# RK3399-AP register map
File version: 1
CPU: CA7 r0p1, little endian, MPU, FPU, I-cache, D-cache, VTOR, 4 interrupt priority bits, 32 interrupts
Registers are 32-bit, read-write, reset 0x0 unless marked. A register's access mark holds for its fields unless they carry their own. Offsets are from the block's base; [hi:lo] are bit positions.

## GPIO0
Base 0xFF720000
Same registers: GPIO1 0xFF730000, GPIO2 0xFF780000, GPIO3 0xFF788000, GPIO4 0xFF790000
0x00 GPIO_SWPORTA_DR — Port A data register
  [31:0] GPIO_SWPORTA_DR — Values written to this register are output on the I/O signals for Port A if the corresponding data direction bits for Port A are set to Output mode. The value read back is equal to the last value written to this register.
0x04 GPIO_SWPORTA_DDR — Port A data direction register
  [31:0] GPIO_SWPORTA_DDR — Values written to this register independently control the direction of the corresponding data bit in Port A. 0: Input (default) 1: Output
0x30 GPIO_INTEN — Interrupt enable register
  [31:0] GPIO_INT_EN — Allows each bit of Port A to be configured for interrupts. Whenever a 1 is written to a bit of this register, it configures the corresponding bit on Port A to become an interrupt; otherwise, Port A operates as a normal GPIO signal. Interrupts are disabled on the corresponding bits of Port A if the corresponding data direction register is set to Output. 0: Configure Port A bit as normal GPIO signal (default) 1: Configure Port A bit as interrupt
0x34 GPIO_INTMASK — Interrupt mask register
  [31:0] GPIO_INT_MASK — Controls whether an interrupt on Port A can create an interrupt for the interrupt controller by not masking it. Whenever a 1 is written to a bit in this register, it masks the interrupt generation capability for this signal; otherwise interrupts are allowed through. 0: Interrupt bits are unmasked (default) 1: Mask interrupt
0x38 GPIO_INTTYPE_LEVEL — Interrupt level register
  [31:0] GPIO_INTTYPE_LEVEL — Controls the type of interrupt that can occur on Port A. 0: Level-sensitive (default) 1: Edge-sensitive
0x3C GPIO_INT_POLARITY — Interrupt polarity register
  [31:0] GPIO_INT_POLARITY — Controls the polarity of edge or level sensitivity that can occur on input of Port A. 0: Active-low (default) 1: Active-high
0x40 GPIO_INT_STATUS ro — Interrupt status of port A
  [31:0] GPIO_INT_STATUS — Interrupt status of Port A
0x44 GPIO_INT_RAWSTATUS ro — Raw Interrupt status of port A
  [31:0] GPIO_INT_RAWSTATUS — Raw interrupt of status of Port A (premasking bits)
0x48 GPIO_DEBOUNCE — Debounce enable register
  [31:0] GPIO_DEBOUNCE — Controls whether an external signal that is the source of an interrupt needs to be debounced to remove any spurious glitches. Writing a 1 to a bit in this register enables the debouncing circuitry. A signal must be valid for two periods of an external clock before it is internally processed. 0: No debounce (default) 1: Enable debounce
0x4C GPIO_PORTA_EOI wo — Port A clear interrupt register
  [31:0] GPIO_PORTA_EOI — Controls the clearing of edge type interrupts from Port A. When a 1 is written into a corresponding bit of this register, the interrupt is cleared. All interrupts are cleared when Port A is not configured for interrupts. 0: No interrupt clear (default) 1: Clear interrupt
0x50 GPIO_EXT_PORTA ro — Port A external port register
  [31:0] GPIO_EXT_PORTA — When Port A is configured as Input, then reading this location reads the values on the signal. When the data direction of Port A is set as Output, reading this location reads the data register for Port A.
0x60 GPIO_LS_SYNC — Level_sensitive synchronization enable register
  [0] GPIO_LS_SYNC — Writing a 1 to this register results in all level-sensitive interrupts being synchronized to pclk_intr. 0: No synchronization to pclk_intr (default) 1: Synchronize to pclk_intr

## EFUSE0
Base 0xFF690000
Same registers: EFUSE1 0xFFFA0000
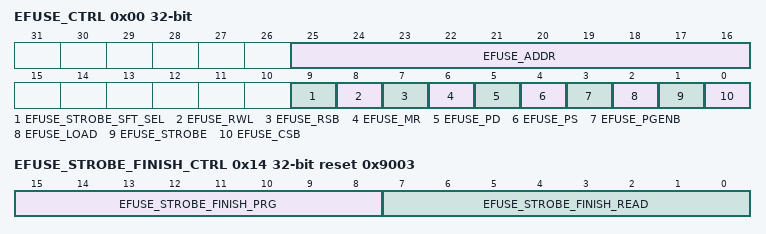
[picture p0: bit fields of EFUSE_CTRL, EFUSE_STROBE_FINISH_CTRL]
0x00 EFUSE_CTRL — efuse control register/eFuse control register
  [25:16] EFUSE_ADDR — efuse address pins :A[9:0]
  [9] EFUSE_STROBE_SFT_SEL — efuse strobe control software mode select, active high
  [8] EFUSE_RWL — efuse redundancy information row select (active high) : RWL
  [7] EFUSE_RSB — efuse redundancy enable(active low) : RSB
  [6] EFUSE_MR — efuse read trip point setting, MR = L for normal read mode; MR = H for margin read1 mode : MR
  [5] EFUSE_PD — efuse power down enable (active high) : PD
  [4] EFUSE_PS — efuse pass 1.8V program voltage to internal for program(active high) : PS
  [3] EFUSE_PGENB — efuse program enable (active low) : PGENB
  [2] EFUSE_LOAD — efuse turn on sense amplifier and load data into latch (active high) : LOAD
  [1] EFUSE_STROBE — efuse turn on the array for read or program access (active high) : STROBE
  [0] EFUSE_CSB — efuse chip select enable signal, active low : CSB
0x04 EFUSE_DOUT ro — efuse data out register/eFuse data out register
  [31:0] EFUSE_DOUT — eFuse data output
0x08 EFUSE_RF ro — efuse redundancy bit used indicator register
  [3:0] EFUSE_RF_R — efuse redundancy bit used indicator register for RF3~RF0, Output high once the redundancy bit has been used.
0x10 EFUSE_JTAG_PASSWD reset 0xCF7680A — Jtag password/eFuse jtag passwd register
  [31:0] JTAG_PASSWD — Jtag password for jtag monitor
0x14 EFUSE_STROBE_FINISH_CTRL reset 0x9003 — efuse strobe finish control register/eFuse jtag passwd register
  [15:8] EFUSE_STROBE_FINISH_PRG — efuse read strobe finish control in hardware mode.
  [7:0] EFUSE_STROBE_FINISH_READ — efuse program strobe finish control in hardware mode.
